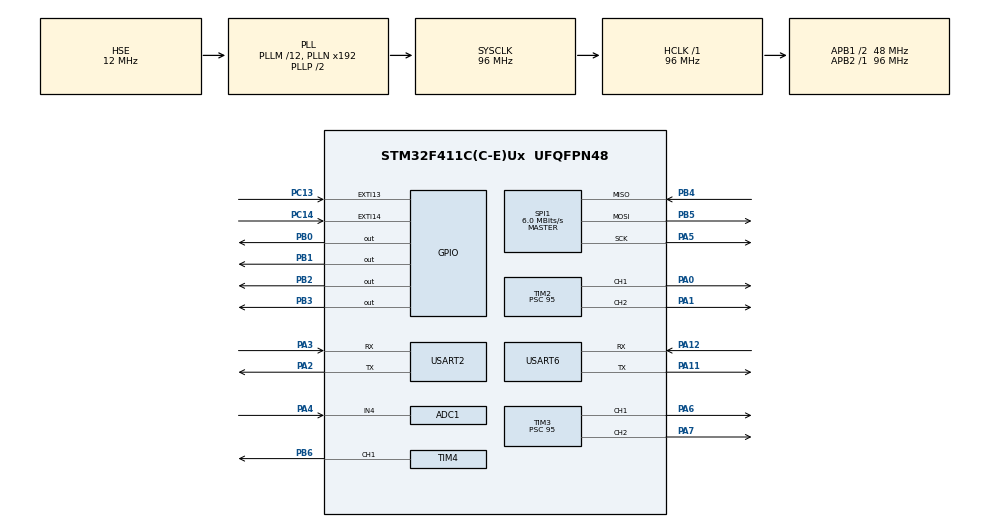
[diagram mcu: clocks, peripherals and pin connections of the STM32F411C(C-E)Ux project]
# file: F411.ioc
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ADC1.Channel-0\#ChannelRegularConversion=ADC_CHANNEL_4
ADC1.NbrOfConversionFlag=1
ADC1.Rank-0\#ChannelRegularConversion=1
ADC1.SamplingTime-0\#ChannelRegularConversion=ADC_SAMPLETIME_84CYCLES
ADC1.master=1
Dma.Request0=USART6_RX
Dma.Request1=USART6_TX
Dma.Request2=USART2_RX
Dma.Request3=USART2_TX
Dma.USART2_RX.2.Direction=DMA_PERIPH_TO_MEMORY
Dma.USART2_RX.2.FIFOMode=DMA_FIFOMODE_DISABLE
Dma.USART2_RX.2.Instance=DMA1_Stream5
Dma.USART2_RX.2.MemDataAlignment=DMA_MDATAALIGN_BYTE
Dma.USART2_RX.2.MemInc=DMA_MINC_ENABLE
Dma.USART2_RX.2.Mode=DMA_CIRCULAR
Dma.USART2_RX.2.PeriphDataAlignment=DMA_PDATAALIGN_BYTE
Dma.USART2_RX.2.PeriphInc=DMA_PINC_DISABLE
Dma.USART2_RX.2.Priority=DMA_PRIORITY_LOW
Dma.USART2_TX.3.Direction=DMA_MEMORY_TO_PERIPH
Dma.USART2_TX.3.FIFOMode=DMA_FIFOMODE_DISABLE
Dma.USART2_TX.3.Instance=DMA1_Stream6
Dma.USART2_TX.3.MemDataAlignment=DMA_MDATAALIGN_BYTE
Dma.USART2_TX.3.MemInc=DMA_MINC_ENABLE
Dma.USART2_TX.3.Mode=DMA_NORMAL
Dma.USART2_TX.3.PeriphDataAlignment=DMA_PDATAALIGN_BYTE
Dma.USART2_TX.3.PeriphInc=DMA_PINC_DISABLE
Dma.USART2_TX.3.Priority=DMA_PRIORITY_LOW
Dma.USART6_RX.0.Direction=DMA_PERIPH_TO_MEMORY
Dma.USART6_RX.0.FIFOMode=DMA_FIFOMODE_DISABLE
Dma.USART6_RX.0.Instance=DMA2_Stream1
Dma.USART6_RX.0.MemDataAlignment=DMA_MDATAALIGN_BYTE
Dma.USART6_RX.0.MemInc=DMA_MINC_ENABLE
Dma.USART6_RX.0.Mode=DMA_CIRCULAR
Dma.USART6_RX.0.PeriphDataAlignment=DMA_PDATAALIGN_BYTE
Dma.USART6_RX.0.PeriphInc=DMA_PINC_DISABLE
Dma.USART6_RX.0.Priority=DMA_PRIORITY_LOW
Dma.USART6_TX.1.Direction=DMA_MEMORY_TO_PERIPH
Dma.USART6_TX.1.FIFOMode=DMA_FIFOMODE_DISABLE
Dma.USART6_TX.1.Instance=DMA2_Stream6
Dma.USART6_TX.1.MemDataAlignment=DMA_MDATAALIGN_BYTE
Dma.USART6_TX.1.MemInc=DMA_MINC_ENABLE
Dma.USART6_TX.1.Mode=DMA_CIRCULAR
Dma.USART6_TX.1.PeriphDataAlignment=DMA_PDATAALIGN_BYTE
Dma.USART6_TX.1.PeriphInc=DMA_PINC_DISABLE
Dma.USART6_TX.1.Priority=DMA_PRIORITY_LOW
FREERTOS.Tasks01=defaultTask,24,128,StartDefaultTask,Default,NULL,Dynamic,NULL,NULL
Mcu.Family=STM32F4
Mcu.Name=STM32F411C(C-E)Ux
Mcu.Package=UFQFPN48
NVIC.DMA1_Stream5_IRQn=true\:5\:0\:false\:false\:true\:true\:false\:true\:true
NVIC.DMA1_Stream6_IRQn=true\:5\:0\:false\:false\:true\:true\:false\:true\:true
NVIC.DMA2_Stream1_IRQn=true\:5\:0\:false\:false\:true\:true\:false\:true\:true
NVIC.DMA2_Stream6_IRQn=true\:5\:0\:false\:false\:true\:true\:false\:true\:true
NVIC.EXTI15_10_IRQn=true\:5\:0\:false\:false\:true\:true\:true\:true\:true
NVIC.PriorityGroup=NVIC_PRIORITYGROUP_4
NVIC.TIM1_UP_TIM10_IRQn=true\:15\:0\:false\:false\:true\:false\:false\:true\:true
NVIC.TimeBase=TIM1_UP_TIM10_IRQn
NVIC.TimeBaseIP=TIM1
NVIC.USART2_IRQn=true\:5\:0\:false\:false\:true\:true\:false\:true\:true
NVIC.USART6_IRQn=true\:5\:0\:false\:false\:true\:true\:false\:true\:true
PA0-WKUP.Signal=S_TIM2_CH1_ETR
PA1.Signal=S_TIM2_CH2
PA11.Mode=Asynchronous
PA11.Signal=USART6_TX
PA12.Mode=Asynchronous
PA12.Signal=USART6_RX
PA13.Mode=Serial_Wire
PA13.Signal=SYS_JTMS-SWDIO
PA14.Mode=Serial_Wire
PA14.Signal=SYS_JTCK-SWCLK
PA2.Mode=Asynchronous
PA2.Signal=USART2_TX
PA3.Mode=Asynchronous
PA3.Signal=USART2_RX
PA4.Signal=ADCx_IN4
PA5.Mode=Full_Duplex_Master
PA5.Signal=SPI1_SCK
PA6.Signal=S_TIM3_CH1
PA7.Signal=S_TIM3_CH2
PB0.Signal=GPIO_Output
PB1.Signal=GPIO_Output
PB2.PinState=GPIO_PIN_SET
PB2.Signal=GPIO_Output
PB3.PinState=GPIO_PIN_SET
PB3.Signal=GPIO_Output
PB4.Mode=Full_Duplex_Master
PB4.Signal=SPI1_MISO
PB5.Mode=Full_Duplex_Master
PB5.Signal=SPI1_MOSI
PB6.Signal=S_TIM4_CH1
PC13-ANTI_TAMP.Signal=GPXTI13
PC14-OSC32_IN.Signal=GPXTI14
PH0\ -\ OSC_IN.Mode=HSE-External-Oscillator
PH0\ -\ OSC_IN.Signal=RCC_OSC_IN
PH1\ -\ OSC_OUT.Mode=HSE-External-Oscillator
PH1\ -\ OSC_OUT.Signal=RCC_OSC_OUT
ProjectManager.HeapSize=0x200
ProjectManager.StackSize=0x400
ProjectManager.TargetToolchain=MDK-ARM V5.32
RCC.48MHZClocksFreq_Value=48000000
RCC.AHBFreq_Value=96000000
RCC.APB1CLKDivider=RCC_HCLK_DIV2
RCC.APB1Freq_Value=48000000
RCC.APB1TimFreq_Value=96000000
RCC.APB2Freq_Value=96000000
RCC.APB2TimFreq_Value=96000000
RCC.CortexFreq_Value=96000000
RCC.HCLKFreq_Value=96000000
RCC.HSE_VALUE=12000000
RCC.HSI_VALUE=16000000
RCC.LSE_VALUE=32768
RCC.PLLM=12
RCC.PLLSourceVirtual=RCC_PLLSOURCE_HSE
RCC.SYSCLKFreq_VALUE=96000000
RCC.SYSCLKSource=RCC_SYSCLKSOURCE_PLLCLK
RCC.VCOOutputFreq_Value=192000000
SH.ADCx_IN4.0=ADC1_IN4,IN4
SH.S_TIM2_CH1_ETR.0=TIM2_CH1,PWM Generation1 CH1
SH.S_TIM2_CH2.0=TIM2_CH2,PWM Generation2 CH2
SH.S_TIM3_CH1.0=TIM3_CH1,PWM Generation1 CH1
SH.S_TIM3_CH2.0=TIM3_CH2,PWM Generation2 CH2
SH.S_TIM4_CH1.0=TIM4_CH1,PWM Generation1 CH1
SPI1.BaudRatePrescaler=SPI_BAUDRATEPRESCALER_16
SPI1.CalculateBaudRate=6.0 MBits/s
SPI1.Direction=SPI_DIRECTION_2LINES
SPI1.CLKPolarity=SPI_POLARITY_HIGH
SPI1.CLKPhase=SPI_PHASE_2EDGE
SPI1.Mode=SPI_MODE_MASTER
SPI1.VirtualType=VM_MASTER
TIM2.Channel-PWM\ Generation1\ CH1=TIM_CHANNEL_1
TIM2.Channel-PWM\ Generation2\ CH2=TIM_CHANNEL_2
TIM2.Period=19999
TIM2.Prescaler=95
TIM3.Channel-PWM\ Generation1\ CH1=TIM_CHANNEL_1
TIM3.Channel-PWM\ Generation2\ CH2=TIM_CHANNEL_2
TIM3.Period=19999
TIM3.Prescaler=95
TIM4.Channel-PWM\ Generation1\ CH1=TIM_CHANNEL_1
TIM4.Period=999
USART2.VirtualMode=VM_ASYNC
USART6.VirtualMode=VM_ASYNC
VP_FREERTOS_VS_CMSIS_V2.Mode=CMSIS_V2
VP_SYS_VS_tim1.Mode=TIM1
board=custom

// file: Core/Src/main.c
/* USER CODE BEGIN Header */
/**
  ******************************************************************************
  * @file           : main.c
  * @brief          : Main program body
  ******************************************************************************
  * @attention
  *
  * Copyright (c) 2026 STMicroelectronics.
  * All rights reserved.
  *
  * This software is licensed under terms that can be found in the LICENSE file
  * in the root directory of this software component.
  * If no LICENSE file comes with this software, it is provided AS-IS.
  *
  ******************************************************************************
  */
/* USER CODE END Header */
#include "main.h"
#include "cmsis_os.h"

/* USER CODE BEGIN Includes */
#include "user_freertos.h"

/* USER CODE END Includes */

ADC_HandleTypeDef hadc1;

SPI_HandleTypeDef hspi1;

TIM_HandleTypeDef htim2;
TIM_HandleTypeDef htim3;
TIM_HandleTypeDef htim4;

UART_HandleTypeDef huart2;
UART_HandleTypeDef huart6;
DMA_HandleTypeDef hdma_usart2_rx;
DMA_HandleTypeDef hdma_usart2_tx;
DMA_HandleTypeDef hdma_usart6_rx;
DMA_HandleTypeDef hdma_usart6_tx;

/* Definitions for defaultTask */
osThreadId_t defaultTaskHandle;
const osThreadAttr_t defaultTask_attributes = {
  .name = "defaultTask",
  .stack_size = 128 * 4,
  .priority = (osPriority_t) osPriorityNormal,
};

void SystemClock_Config(void);
static void MX_GPIO_Init(void);
static void MX_DMA_Init(void);
static void MX_SPI1_Init(void);
static void MX_USART2_UART_Init(void);
static void MX_USART6_UART_Init(void);
static void MX_ADC1_Init(void);
static void MX_TIM2_Init(void);
static void MX_TIM3_Init(void);
static void MX_TIM4_Init(void);
void StartDefaultTask(void *argument);

int main(void)
{

  /* MCU Configuration--------------------------------------------------------*/

  /* Reset of all peripherals, Initializes the Flash interface and the Systick. */
  HAL_Init();

  /* Configure the system clock */
  SystemClock_Config();

  /* Initialize all configured peripherals */
  MX_GPIO_Init();
  MX_DMA_Init();
  MX_SPI1_Init();
  MX_USART2_UART_Init();
  MX_USART6_UART_Init();
  MX_ADC1_Init();
  MX_TIM2_Init();
  MX_TIM3_Init();
  MX_TIM4_Init();

  /* Init scheduler */
  osKernelInitialize();

  /* Create the thread(s) */
  /* creation of defaultTask */
  defaultTaskHandle = osThreadNew(StartDefaultTask, NULL, &defaultTask_attributes);

  /* USER CODE BEGIN RTOS_THREADS */
  MX_USER_FREERTOS_Init();
  /* add threads, ... */
  /* USER CODE END RTOS_THREADS */

  /* Start scheduler */
  osKernelStart();

  /* We should never get here as control is now taken by the scheduler */

  /* Infinite loop */
  while (1)
  {

  }
}

void SystemClock_Config(void)
{
  RCC_OscInitTypeDef RCC_OscInitStruct = {0};
  RCC_ClkInitTypeDef RCC_ClkInitStruct = {0};

  /** Configure the main internal regulator output voltage
  */
  __HAL_RCC_PWR_CLK_ENABLE();
  __HAL_PWR_VOLTAGESCALING_CONFIG(PWR_REGULATOR_VOLTAGE_SCALE1);

  /** Initializes the RCC Oscillators according to the specified parameters
  * in the RCC_OscInitTypeDef structure.
  */
  RCC_OscInitStruct.OscillatorType = RCC_OSCILLATORTYPE_HSE;
  RCC_OscInitStruct.HSEState = RCC_HSE_ON;
  RCC_OscInitStruct.PLL.PLLState = RCC_PLL_ON;
  RCC_OscInitStruct.PLL.PLLSource = RCC_PLLSOURCE_HSE;
  RCC_OscInitStruct.PLL.PLLM = 12;
  RCC_OscInitStruct.PLL.PLLN = 192;
  RCC_OscInitStruct.PLL.PLLP = RCC_PLLP_DIV2;
  RCC_OscInitStruct.PLL.PLLQ = 4;
  if (HAL_RCC_OscConfig(&RCC_OscInitStruct) != HAL_OK)
  {
    Error_Handler();
  }

  /** Initializes the CPU, AHB and APB buses clocks
  */
  RCC_ClkInitStruct.ClockType = RCC_CLOCKTYPE_HCLK|RCC_CLOCKTYPE_SYSCLK
                              |RCC_CLOCKTYPE_PCLK1|RCC_CLOCKTYPE_PCLK2;
  RCC_ClkInitStruct.SYSCLKSource = RCC_SYSCLKSOURCE_PLLCLK;
  RCC_ClkInitStruct.AHBCLKDivider = RCC_SYSCLK_DIV1;
  RCC_ClkInitStruct.APB1CLKDivider = RCC_HCLK_DIV2;
  RCC_ClkInitStruct.APB2CLKDivider = RCC_HCLK_DIV1;

  if (HAL_RCC_ClockConfig(&RCC_ClkInitStruct, FLASH_LATENCY_3) != HAL_OK)
  {
    Error_Handler();
  }
}

static void MX_ADC1_Init(void)
{

  ADC_ChannelConfTypeDef sConfig = {0};

  /** Configure the global features of the ADC (Clock, Resolution, Data Alignment and number of conversion)
  */
  hadc1.Instance = ADC1;
  hadc1.Init.ClockPrescaler = ADC_CLOCK_SYNC_PCLK_DIV4;
  hadc1.Init.Resolution = ADC_RESOLUTION_12B;
  hadc1.Init.ScanConvMode = DISABLE;
  hadc1.Init.ContinuousConvMode = DISABLE;
  hadc1.Init.DiscontinuousConvMode = DISABLE;
  hadc1.Init.ExternalTrigConvEdge = ADC_EXTERNALTRIGCONVEDGE_NONE;
  hadc1.Init.ExternalTrigConv = ADC_SOFTWARE_START;
  hadc1.Init.DataAlign = ADC_DATAALIGN_RIGHT;
  hadc1.Init.NbrOfConversion = 1;
  hadc1.Init.DMAContinuousRequests = DISABLE;
  hadc1.Init.EOCSelection = ADC_EOC_SINGLE_CONV;
  if (HAL_ADC_Init(&hadc1) != HAL_OK)
  {
    Error_Handler();
  }

  /** Configure for the selected ADC regular channel its corresponding rank in the sequencer and its sample time.
  */
  sConfig.Channel = ADC_CHANNEL_4;
  sConfig.Rank = 1;
  sConfig.SamplingTime = ADC_SAMPLETIME_84CYCLES;
  if (HAL_ADC_ConfigChannel(&hadc1, &sConfig) != HAL_OK)
  {
    Error_Handler();
  }

}

static void MX_SPI1_Init(void)
{

  /* SPI1 parameter configuration*/
  hspi1.Instance = SPI1;
  hspi1.Init.Mode = SPI_MODE_MASTER;
  hspi1.Init.Direction = SPI_DIRECTION_2LINES;
  hspi1.Init.DataSize = SPI_DATASIZE_8BIT;
  hspi1.Init.CLKPolarity = SPI_POLARITY_HIGH;
  hspi1.Init.CLKPhase = SPI_PHASE_2EDGE;
  hspi1.Init.NSS = SPI_NSS_SOFT;
  hspi1.Init.BaudRatePrescaler = SPI_BAUDRATEPRESCALER_16;
  hspi1.Init.FirstBit = SPI_FIRSTBIT_MSB;
  hspi1.Init.TIMode = SPI_TIMODE_DISABLE;
  hspi1.Init.CRCCalculation = SPI_CRCCALCULATION_DISABLE;
  hspi1.Init.CRCPolynomial = 10;
  if (HAL_SPI_Init(&hspi1) != HAL_OK)
  {
    Error_Handler();
  }

}

static void MX_TIM2_Init(void)
{

  TIM_MasterConfigTypeDef sMasterConfig = {0};
  TIM_OC_InitTypeDef sConfigOC = {0};

  htim2.Instance = TIM2;
  htim2.Init.Prescaler = 95;
  htim2.Init.CounterMode = TIM_COUNTERMODE_UP;
  htim2.Init.Period = 19999;
  htim2.Init.ClockDivision = TIM_CLOCKDIVISION_DIV1;
  htim2.Init.AutoReloadPreload = TIM_AUTORELOAD_PRELOAD_DISABLE;
  if (HAL_TIM_PWM_Init(&htim2) != HAL_OK)
  {
    Error_Handler();
  }
  sMasterConfig.MasterOutputTrigger = TIM_TRGO_RESET;
  sMasterConfig.MasterSlaveMode = TIM_MASTERSLAVEMODE_DISABLE;
  if (HAL_TIMEx_MasterConfigSynchronization(&htim2, &sMasterConfig) != HAL_OK)
  {
    Error_Handler();
  }
  sConfigOC.OCMode = TIM_OCMODE_PWM1;
  sConfigOC.Pulse = 0;
  sConfigOC.OCPolarity = TIM_OCPOLARITY_HIGH;
  sConfigOC.OCFastMode = TIM_OCFAST_DISABLE;
  if (HAL_TIM_PWM_ConfigChannel(&htim2, &sConfigOC, TIM_CHANNEL_1) != HAL_OK)
  {
    Error_Handler();
  }
  if (HAL_TIM_PWM_ConfigChannel(&htim2, &sConfigOC, TIM_CHANNEL_2) != HAL_OK)
  {
    Error_Handler();
  }
  HAL_TIM_MspPostInit(&htim2);

}

static void MX_TIM3_Init(void)
{

  TIM_MasterConfigTypeDef sMasterConfig = {0};
  TIM_OC_InitTypeDef sConfigOC = {0};

  htim3.Instance = TIM3;
  htim3.Init.Prescaler = 95;
  htim3.Init.CounterMode = TIM_COUNTERMODE_UP;
  htim3.Init.Period = 19999;
  htim3.Init.ClockDivision = TIM_CLOCKDIVISION_DIV1;
  htim3.Init.AutoReloadPreload = TIM_AUTORELOAD_PRELOAD_DISABLE;
  if (HAL_TIM_PWM_Init(&htim3) != HAL_OK)
  {
    Error_Handler();
  }
  sMasterConfig.MasterOutputTrigger = TIM_TRGO_RESET;
  sMasterConfig.MasterSlaveMode = TIM_MASTERSLAVEMODE_DISABLE;
  if (HAL_TIMEx_MasterConfigSynchronization(&htim3, &sMasterConfig) != HAL_OK)
  {
    Error_Handler();
  }
  sConfigOC.OCMode = TIM_OCMODE_PWM1;
  sConfigOC.Pulse = 0;
  sConfigOC.OCPolarity = TIM_OCPOLARITY_HIGH;
  sConfigOC.OCFastMode = TIM_OCFAST_DISABLE;
  if (HAL_TIM_PWM_ConfigChannel(&htim3, &sConfigOC, TIM_CHANNEL_1) != HAL_OK)
  {
    Error_Handler();
  }
  if (HAL_TIM_PWM_ConfigChannel(&htim3, &sConfigOC, TIM_CHANNEL_2) != HAL_OK)
  {
    Error_Handler();
  }
  HAL_TIM_MspPostInit(&htim3);

}

static void MX_TIM4_Init(void)
{

  TIM_MasterConfigTypeDef sMasterConfig = {0};
  TIM_OC_InitTypeDef sConfigOC = {0};

  htim4.Instance = TIM4;
  htim4.Init.Prescaler = 0;
  htim4.Init.CounterMode = TIM_COUNTERMODE_UP;
  htim4.Init.Period = 999;
  htim4.Init.ClockDivision = TIM_CLOCKDIVISION_DIV1;
  htim4.Init.AutoReloadPreload = TIM_AUTORELOAD_PRELOAD_DISABLE;
  if (HAL_TIM_PWM_Init(&htim4) != HAL_OK)
  {
    Error_Handler();
  }
  sMasterConfig.MasterOutputTrigger = TIM_TRGO_RESET;
  sMasterConfig.MasterSlaveMode = TIM_MASTERSLAVEMODE_DISABLE;
  if (HAL_TIMEx_MasterConfigSynchronization(&htim4, &sMasterConfig) != HAL_OK)
  {
    Error_Handler();
  }
  sConfigOC.OCMode = TIM_OCMODE_PWM1;
  sConfigOC.Pulse = 0;
  sConfigOC.OCPolarity = TIM_OCPOLARITY_HIGH;
  sConfigOC.OCFastMode = TIM_OCFAST_DISABLE;
  if (HAL_TIM_PWM_ConfigChannel(&htim4, &sConfigOC, TIM_CHANNEL_1) != HAL_OK)
  {
    Error_Handler();
  }
  HAL_TIM_MspPostInit(&htim4);

}

static void MX_USART2_UART_Init(void)
{

  huart2.Instance = USART2;
  huart2.Init.BaudRate = 115200;
  huart2.Init.WordLength = UART_WORDLENGTH_8B;
  huart2.Init.StopBits = UART_STOPBITS_1;
  huart2.Init.Parity = UART_PARITY_NONE;
  huart2.Init.Mode = UART_MODE_TX_RX;
  huart2.Init.HwFlowCtl = UART_HWCONTROL_NONE;
  huart2.Init.OverSampling = UART_OVERSAMPLING_16;
  if (HAL_UART_Init(&huart2) != HAL_OK)
  {
    Error_Handler();
  }

}

static void MX_USART6_UART_Init(void)
{

  huart6.Instance = USART6;
  huart6.Init.BaudRate = 115200;
  huart6.Init.WordLength = UART_WORDLENGTH_8B;
  huart6.Init.StopBits = UART_STOPBITS_1;
  huart6.Init.Parity = UART_PARITY_NONE;
  huart6.Init.Mode = UART_MODE_TX_RX;
  huart6.Init.HwFlowCtl = UART_HWCONTROL_NONE;
  huart6.Init.OverSampling = UART_OVERSAMPLING_16;
  if (HAL_UART_Init(&huart6) != HAL_OK)
  {
    Error_Handler();
  }

}

static void MX_DMA_Init(void)
{

  /* DMA controller clock enable */
  __HAL_RCC_DMA2_CLK_ENABLE();
  __HAL_RCC_DMA1_CLK_ENABLE();

  /* DMA interrupt init */
  /* DMA1_Stream5_IRQn interrupt configuration */
  HAL_NVIC_SetPriority(DMA1_Stream5_IRQn, 5, 0);
  HAL_NVIC_EnableIRQ(DMA1_Stream5_IRQn);
  /* DMA1_Stream6_IRQn interrupt configuration */
  HAL_NVIC_SetPriority(DMA1_Stream6_IRQn, 5, 0);
  HAL_NVIC_EnableIRQ(DMA1_Stream6_IRQn);
  /* DMA2_Stream1_IRQn interrupt configuration */
  HAL_NVIC_SetPriority(DMA2_Stream1_IRQn, 5, 0);
  HAL_NVIC_EnableIRQ(DMA2_Stream1_IRQn);
  /* DMA2_Stream6_IRQn interrupt configuration */
  HAL_NVIC_SetPriority(DMA2_Stream6_IRQn, 5, 0);
  HAL_NVIC_EnableIRQ(DMA2_Stream6_IRQn);

}

static void MX_GPIO_Init(void)
{
  GPIO_InitTypeDef GPIO_InitStruct = {0};

  /* GPIO Ports Clock Enable */
  __HAL_RCC_GPIOC_CLK_ENABLE();
  __HAL_RCC_GPIOH_CLK_ENABLE();
  __HAL_RCC_GPIOA_CLK_ENABLE();
  __HAL_RCC_GPIOB_CLK_ENABLE();

  /*Configure GPIO pin Output Level */
  HAL_GPIO_WritePin(GPIOB, GPIO_PIN_0|GPIO_PIN_1, GPIO_PIN_RESET);

  /*Configure GPIO pin Output Level */
  HAL_GPIO_WritePin(GPIOB, GPIO_PIN_2|GPIO_PIN_3, GPIO_PIN_SET);

  /*Configure GPIO pins : PC13 PC14 */
  GPIO_InitStruct.Pin = GPIO_PIN_13|GPIO_PIN_14;
  GPIO_InitStruct.Mode = GPIO_MODE_IT_RISING;
  GPIO_InitStruct.Pull = GPIO_NOPULL;
  HAL_GPIO_Init(GPIOC, &GPIO_InitStruct);

  /*Configure GPIO pins : PB0 PB1 PB2 PB3 */
  GPIO_InitStruct.Pin = GPIO_PIN_0|GPIO_PIN_1|GPIO_PIN_2|GPIO_PIN_3;
  GPIO_InitStruct.Mode = GPIO_MODE_OUTPUT_PP;
  GPIO_InitStruct.Pull = GPIO_NOPULL;
  GPIO_InitStruct.Speed = GPIO_SPEED_FREQ_LOW;
  HAL_GPIO_Init(GPIOB, &GPIO_InitStruct);

  /* EXTI interrupt init*/
  HAL_NVIC_SetPriority(EXTI15_10_IRQn, 5, 0);
  HAL_NVIC_EnableIRQ(EXTI15_10_IRQn);

}

void StartDefaultTask(void *argument)
{
  for(;;)
  {
    osDelay(1);
  }
}

void HAL_TIM_PeriodElapsedCallback(TIM_HandleTypeDef *htim)
{
  if (htim->Instance == TIM1) {
    HAL_IncTick();
  }
}

void Error_Handler(void)
{
  __disable_irq();
  while (1)
  {
  }
}
